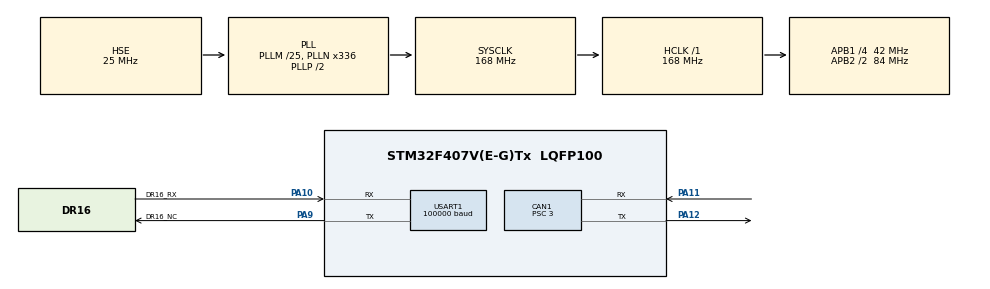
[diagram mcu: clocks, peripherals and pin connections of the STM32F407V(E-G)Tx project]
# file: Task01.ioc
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CAN1.BS1=CAN_BS1_10TQ
CAN1.BS2=CAN_BS2_4TQ
CAN1.CalculateBaudRate=933333
CAN1.CalculateTimeBit=1071.42
CAN1.CalculateTimeQuantum=71.42857142857143
CAN1.Prescaler=3
Dma.Request0=USART1_RX
Dma.USART1_RX.0.Direction=DMA_PERIPH_TO_MEMORY
Dma.USART1_RX.0.FIFOMode=DMA_FIFOMODE_DISABLE
Dma.USART1_RX.0.Instance=DMA2_Stream2
Dma.USART1_RX.0.MemDataAlignment=DMA_MDATAALIGN_BYTE
Dma.USART1_RX.0.MemInc=DMA_MINC_ENABLE
Dma.USART1_RX.0.Mode=DMA_NORMAL
Dma.USART1_RX.0.PeriphDataAlignment=DMA_PDATAALIGN_BYTE
Dma.USART1_RX.0.PeriphInc=DMA_PINC_DISABLE
Dma.USART1_RX.0.Priority=DMA_PRIORITY_VERY_HIGH
FREERTOS.Queues01=MsgToMt,16,uint32_t,0,Dynamic,NULL,NULL
FREERTOS.Tasks01=Msg,0,128,taskMsg,Default,NULL,Dynamic,NULL,NULL;Motor,-3,128,taskMotor,Default,NULL,Dynamic,NULL,NULL
Mcu.Family=STM32F4
Mcu.Name=STM32F407V(E-G)Tx
Mcu.Package=LQFP100
NVIC.CAN1_RX0_IRQn=true\:5\:0\:false\:false\:true\:true\:true\:true
NVIC.CAN1_TX_IRQn=true\:5\:0\:false\:false\:true\:true\:true\:true
NVIC.DMA2_Stream2_IRQn=true\:5\:0\:false\:false\:true\:true\:false\:true
NVIC.PriorityGroup=NVIC_PRIORITYGROUP_4
NVIC.TIM6_DAC_IRQn=true\:0\:0\:false\:false\:true\:false\:false\:true
NVIC.TimeBase=TIM6_DAC_IRQn
NVIC.TimeBaseIP=TIM6
NVIC.USART1_IRQn=true\:5\:0\:false\:false\:true\:true\:true\:true
PA10.GPIO_Label=DR16_RX
PA10.Mode=Asynchronous
PA10.Signal=USART1_RX
PA11.Mode=CAN_Activate
PA11.Signal=CAN1_RX
PA12.Mode=CAN_Activate
PA12.Signal=CAN1_TX
PA13.Mode=Serial_Wire
PA13.Signal=SYS_JTMS-SWDIO
PA14.Mode=Serial_Wire
PA14.Signal=SYS_JTCK-SWCLK
PA9.GPIO_Label=DR16_NC
PA9.Mode=Asynchronous
PA9.Signal=USART1_TX
PH0-OSC_IN.Mode=HSE-External-Oscillator
PH0-OSC_IN.Signal=RCC_OSC_IN
PH1-OSC_OUT.Mode=HSE-External-Oscillator
PH1-OSC_OUT.Signal=RCC_OSC_OUT
ProjectManager.HeapSize=0x200
ProjectManager.StackSize=0x400
ProjectManager.TargetToolchain=MDK-ARM V5.27
RCC.48MHZClocksFreq_Value=84000000
RCC.AHBFreq_Value=168000000
RCC.APB1CLKDivider=RCC_HCLK_DIV4
RCC.APB1Freq_Value=42000000
RCC.APB1TimFreq_Value=84000000
RCC.APB2CLKDivider=RCC_HCLK_DIV2
RCC.APB2Freq_Value=84000000
RCC.APB2TimFreq_Value=168000000
RCC.CortexFreq_Value=168000000
RCC.HCLKFreq_Value=168000000
RCC.HSE_VALUE=25000000
RCC.HSI_VALUE=16000000
RCC.LSE_VALUE=32768
RCC.PLLM=25
RCC.PLLN=336
RCC.PLLSourceVirtual=RCC_PLLSOURCE_HSE
RCC.SYSCLKFreq_VALUE=168000000
RCC.SYSCLKSource=RCC_SYSCLKSOURCE_PLLCLK
RCC.VCOOutputFreq_Value=336000000
USART1.BaudRate=100000
USART1.Parity=PARITY_EVEN
USART1.VirtualMode=VM_ASYNC
USART1.WordLength=WORDLENGTH_9B
VP_FREERTOS_VS_CMSIS_V1.Mode=CMSIS_V1
VP_SYS_VS_tim6.Mode=TIM6
board=custom

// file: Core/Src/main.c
/* USER CODE BEGIN Header */
/**
  ******************************************************************************
  * @file           : main.c
  * @brief          : Main program body
  ******************************************************************************
  * @attention
  *
  * <h2><center>&copy; Copyright (c) 2021 STMicroelectronics.
  * All rights reserved.</center></h2>
  *
  * This software component is licensed by ST under Ultimate Liberty license
  * SLA0044, the "License"; You may not use this file except in compliance with
  * the License. You may obtain a copy of the License at:
  *                             www.st.com/SLA0044
  *
  ******************************************************************************
  */
/* USER CODE END Header */
#include "main.h"
#include "cmsis_os.h"
#include "can.h"
#include "dma.h"
#include "usart.h"
#include "gpio.h"

void SystemClock_Config(void);
void MX_FREERTOS_Init(void);

int main(void)
{

  /* MCU Configuration--------------------------------------------------------*/

  /* Reset of all peripherals, Initializes the Flash interface and the Systick. */
  HAL_Init();

  /* Configure the system clock */
  SystemClock_Config();

  /* Initialize all configured peripherals */
  MX_GPIO_Init();
  MX_DMA_Init();
  MX_CAN1_Init();
  MX_USART1_UART_Init();

  /* Call init function for freertos objects (in freertos.c) */
  MX_FREERTOS_Init();
  /* Start scheduler */
  osKernelStart();

  /* We should never get here as control is now taken by the scheduler */
  /* Infinite loop */
  while (1)
  {

  }
}

void SystemClock_Config(void)
{
  RCC_OscInitTypeDef RCC_OscInitStruct = {0};
  RCC_ClkInitTypeDef RCC_ClkInitStruct = {0};

  /** Configure the main internal regulator output voltage
  */
  __HAL_RCC_PWR_CLK_ENABLE();
  __HAL_PWR_VOLTAGESCALING_CONFIG(PWR_REGULATOR_VOLTAGE_SCALE1);
  /** Initializes the RCC Oscillators according to the specified parameters
  * in the RCC_OscInitTypeDef structure.
  */
  RCC_OscInitStruct.OscillatorType = RCC_OSCILLATORTYPE_HSE;
  RCC_OscInitStruct.HSEState = RCC_HSE_ON;
  RCC_OscInitStruct.PLL.PLLState = RCC_PLL_ON;
  RCC_OscInitStruct.PLL.PLLSource = RCC_PLLSOURCE_HSE;
  RCC_OscInitStruct.PLL.PLLM = 25;
  RCC_OscInitStruct.PLL.PLLN = 336;
  RCC_OscInitStruct.PLL.PLLP = RCC_PLLP_DIV2;
  RCC_OscInitStruct.PLL.PLLQ = 4;
  if (HAL_RCC_OscConfig(&RCC_OscInitStruct) != HAL_OK)
  {
    Error_Handler();
  }
  /** Initializes the CPU, AHB and APB buses clocks
  */
  RCC_ClkInitStruct.ClockType = RCC_CLOCKTYPE_HCLK|RCC_CLOCKTYPE_SYSCLK
                              |RCC_CLOCKTYPE_PCLK1|RCC_CLOCKTYPE_PCLK2;
  RCC_ClkInitStruct.SYSCLKSource = RCC_SYSCLKSOURCE_PLLCLK;
  RCC_ClkInitStruct.AHBCLKDivider = RCC_SYSCLK_DIV1;
  RCC_ClkInitStruct.APB1CLKDivider = RCC_HCLK_DIV4;
  RCC_ClkInitStruct.APB2CLKDivider = RCC_HCLK_DIV2;

  if (HAL_RCC_ClockConfig(&RCC_ClkInitStruct, FLASH_LATENCY_5) != HAL_OK)
  {
    Error_Handler();
  }
}

 /**
  * @brief  Period elapsed callback in non blocking mode
  * @note   This function is called  when TIM6 interrupt took place, inside
  * HAL_TIM_IRQHandler(). It makes a direct call to HAL_IncTick() to increment
  * a global variable "uwTick" used as application time base.
  * @param  htim : TIM handle
  * @retval None
  */
void HAL_TIM_PeriodElapsedCallback(TIM_HandleTypeDef *htim)
{
  if (htim->Instance == TIM6) {
    HAL_IncTick();
  }
}

void Error_Handler(void)
{
  __disable_irq();
  while (1)
  {
  }
}

/************************ (C) COPYRIGHT STMicroelectronics *****END OF FILE****/

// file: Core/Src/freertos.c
/* USER CODE BEGIN Header */
/**
  ******************************************************************************
  * File Name          : freertos.c
  * Description        : Code for freertos applications
  ******************************************************************************
  * @attention
  *
  * <h2><center>&copy; Copyright (c) 2021 STMicroelectronics.
  * All rights reserved.</center></h2>
  *
  * This software component is licensed by ST under Ultimate Liberty license
  * SLA0044, the "License"; You may not use this file except in compliance with
  * the License. You may obtain a copy of the License at:
  *                             www.st.com/SLA0044
  *
  ******************************************************************************
  */
/* USER CODE END Header */

#include "FreeRTOS.h"
#include "task.h"
#include "main.h"
#include "cmsis_os.h"

/* USER CODE BEGIN Includes */
#include "message.h"
/* USER CODE END Includes */

/* USER CODE BEGIN Variables */
osEvent evt;
/* USER CODE END Variables */
osThreadId MsgHandle;
osThreadId MotorHandle;
osMessageQId MsgToMtHandle;

void taskMsg(void const * argument);
void taskMotor(void const * argument);

void MX_FREERTOS_Init(void); /* (MISRA C 2004 rule 8.1) */

/* GetIdleTaskMemory prototype (linked to static allocation support) */
void vApplicationGetIdleTaskMemory( StaticTask_t **ppxIdleTaskTCBBuffer, StackType_t **ppxIdleTaskStackBuffer, uint32_t *pulIdleTaskStackSize );

/* USER CODE BEGIN GET_IDLE_TASK_MEMORY */
static StaticTask_t xIdleTaskTCBBuffer;
static StackType_t xIdleStack[configMINIMAL_STACK_SIZE];

void vApplicationGetIdleTaskMemory( StaticTask_t **ppxIdleTaskTCBBuffer, StackType_t **ppxIdleTaskStackBuffer, uint32_t *pulIdleTaskStackSize )
{
  *ppxIdleTaskTCBBuffer = &xIdleTaskTCBBuffer;
  *ppxIdleTaskStackBuffer = &xIdleStack[0];
  *pulIdleTaskStackSize = configMINIMAL_STACK_SIZE;
  /* place for user code */
}
/* USER CODE END GET_IDLE_TASK_MEMORY */

void MX_FREERTOS_Init(void) {

  /* Create the queue(s) */
  /* definition and creation of MsgToMt */
  osMessageQDef(MsgToMt, 16, uint32_t);
  MsgToMtHandle = osMessageCreate(osMessageQ(MsgToMt), NULL);

  /* Create the thread(s) */
  /* definition and creation of Msg */
  osThreadDef(Msg, taskMsg, osPriorityNormal, 0, 128);
  MsgHandle = osThreadCreate(osThread(Msg), NULL);

  /* definition and creation of Motor */
  osThreadDef(Motor, taskMotor, osPriorityIdle, 0, 128);
  MotorHandle = osThreadCreate(osThread(Motor), NULL);

}

void taskMsg(void const * argument)
{
  /* USER CODE BEGIN taskMsg */
  /* Infinite loop */
  for(;;)
  {
		RemoteData_t RDMsg;
		RemoteDataMsg_Process(&RDMsg);
		osMessagePut(MsgToMtHandle, (uint32_t)&RDMsg, 0);
    osDelay(10);
  }
  /* USER CODE END taskMsg */
}

void taskMotor(void const * argument)
{
  /* USER CODE BEGIN taskMotor */
	 RemoteData_t *RDMsg;
  /* Infinite loop */
  for(;;)
  {
		evt = osMessageGet(MsgToMtHandle,0);
        if(evt.status == osEventMessage)
        {
            RDMsg = (RemoteData_t*)evt.value.v;
        }

        osDelay(5);
  }
  /* USER CODE END taskMotor */
}

/************************ (C) COPYRIGHT STMicroelectronics *****END OF FILE****/
